AUTOSAR XML (schema 00046)
package /ComponentTypes
  swc implementation Ct_MBBL_SsaAppl_TrustModel_Implementation: behavior=Ct_MBBL_SsaAppl_TrustModel_InternalBehavior
    code-descriptors:
      code Default: artifact-descriptors=autosar-engineering-object=category=SWSRC
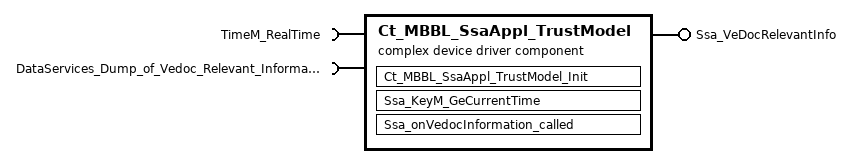
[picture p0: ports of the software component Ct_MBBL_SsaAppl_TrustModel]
  complex device driver sw component type Ct_MBBL_SsaAppl_TrustModel
    require port TimeM_RealTime: required-com-specs=[Compare, Get, Set], required-interface=TimeM_RealTime
    provide port Ssa_VeDocRelevantInfo: server-com-spec{operation=GetData, queue-length=1}, provided-interface=Ssa_VeDocRelevantInfo
    require port DataServices_Dump_of_Vedoc_Relevant_Information_Read_PatchedObject: required-com-specs=[ConditionCheckRead, ReadDataLength, ReadData], required-interface=DataServices_Dump_of_Vedoc_Relevant_Information_Read_PatchedObject
    behavior Ct_MBBL_SsaAppl_TrustModel_InternalBehavior
      ar-typed-per-instance-memorys:
        data Pim_RealTime_Unix: sw-calibration-access=READ-ONLY, type=uint64
      init event Ct_MBBL_SsaAppl_TrustModel_InitEvent: start-on-event=Ct_MBBL_SsaAppl_TrustModel_Init
      operation invoked event OIT_Ssa_onVedocInformation_called_Ssa_VeDocRelevantInfo_GetData: start-on-event=Ssa_onVedocInformation_called, operation=Ssa_VeDocRelevantInfo.GetData
      runnable Ct_MBBL_SsaAppl_TrustModel_Init
      runnable Ssa_KeyM_GeCurrentTime
        sync call SC_TimeM_RealTime_Compare: operation=TimeM_RealTime.Compare
        sync call SC_TimeM_RealTime_Get: operation=TimeM_RealTime.Get
        sync call SC_TimeM_RealTime_Set: operation=TimeM_RealTime.Set
      runnable Ssa_onVedocInformation_called
        sync call SC_DataServices_Dump_of_Vedoc_Relevant_Information_Read_PatchedObject_ReadData: operation=DataServices_Dump_of_Vedoc_Relevant_Information_Read_PatchedObject.ReadData
        sync call SC_DataServices_Dump_of_Vedoc_Relevant_Information_Read_PatchedObject_ReadDataLength: operation=DataServices_Dump_of_Vedoc_Relevant_Information_Read_PatchedObject.ReadDataLength
        sync call SC_DataServices_Dump_of_Vedoc_Relevant_Information_Read_PatchedObject_ConditionCheckRead: operation=DataServices_Dump_of_Vedoc_Relevant_Information_Read_PatchedObject.ConditionCheckRead
